# STM32F098xx register map
File version: 1.0
Registers are 32-bit, read-write, reset 0x0 unless marked. A register's access mark holds for its fields unless they carry their own. Offsets are from the block's base; [hi:lo] are bit positions.

## CEC — HDMI-CEC
Base 0x40007800
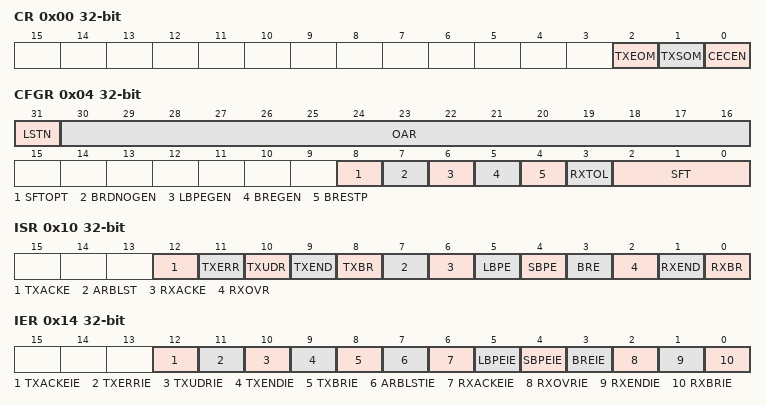
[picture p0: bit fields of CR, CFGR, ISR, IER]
0x00 CR — CEC control register
  [2] TXEOM — CEC Tx End Of Message
  [1] TXSOM — CEC Tx Start Of Message
  [0] CECEN — CEC Enable
0x04 CFGR — CEC configuration register
  [31] LSTN — CEC Listen mode
  [30:16] OAR — CEC Own Address
  [8] SFTOPT — CEC Signal Free Time optional
  [7] BRDNOGEN — CEC Broadcast No Error generation
  [6] LBPEGEN — CEC Long Bit Period Error gener
  [5] BREGEN — CEC Bit Rising Error generation
  [4] BRESTP — CEC Rx Stop
  [3] RXTOL — CEC Tolerance
  [2:0] SFT — CEC Signal Free Time
0x08 TXDR — CEC Tx data register
  [7:0] TXD — CEC Tx Data
0x0C RXDR — CEC Rx Data Register
  [7:0] RXD — CEC Rx Data
0x10 ISR — CEC Interrupt and Status Register
  [12] TXACKE — CEC Tx Missing Acknowledge
  [11] TXERR — CEC Tx-Error
  [10] TXUDR — CEC Tx-Buffer Underrun
  [9] TXEND — CEC End of Transmission
  [8] TXBR — CEC Tx Byte Request
  [7] ARBLST — CEC Arbitration Lost
  [6] RXACKE — CEC Rx Missing Acknowledge
  [5] LBPE — CEC Rx Long Bit period Error
  [4] SBPE — CEC Rx Short Bit period Error
  [3] BRE — CEC Rx Bit Rising Error
  [2] RXOVR — CEC Rx-Overrun
  [1] RXEND — CEC End Of Reception
  [0] RXBR — CEC Rx-Byte Received
0x14 IER — CEC interrupt enable register
  [12] TXACKEIE — CEC Tx Missing Acknowledge IT Enable
  [11] TXERRIE — CEC Tx-Error IT Enable
  [10] TXUDRIE — CEC Tx-Buffer Underrun IT Enable
  [9] TXENDIE — CEC End of Transmission IT Enable
  [8] TXBRIE — CEC Tx Byte Request IT Enable
  [7] ARBLSTIE — CEC Arbitration Lost IT Enable
  [6] RXACKEIE — CEC Rx Missing Acknowledge IT Enable
  [5] LBPEIE — CEC Rx Long Bit period Error IT Enable
  [4] SBPEIE — CEC Rx Short Bit period Error IT Enable
  [3] BREIE — CEC Rx Bit Rising Error IT Enable
  [2] RXOVRIE — CEC Rx-Overrun IT Enable
  [1] RXENDIE — CEC End Of Reception IT Enable
  [0] RXBRIE — CEC Rx-Byte Received IT Enable

## COMP
Base 0x4001001C
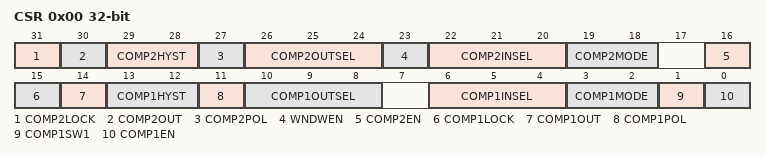
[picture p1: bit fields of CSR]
0x00 CSR — Kept for legacy purpose. Use structure 'COMP_Common_TypeDef'
  [31] COMP2LOCK
  [30] COMP2OUT — COMP2 output level
  [29:28] COMP2HYST — COMP2 hysteresis
  [27] COMP2POL — COMP2 output polarity
  [26:24] COMP2OUTSEL — COMP2 output select
  [23] WNDWEN — COMPx window mode. Bit intended to be used with COMP common instance (COMP_Common_TypeDef)
    0=DISABLE (Window mode disable: Comparators 1 and 2 are independent); 1=COMP1_INPUT_PLUS_COMMON (Window mode enable: Comparators instances pair COMP1 and COMP2 have their input plus connected together. The common input is COMP1 input plus (COMP2 input plus is no more accessible).)
  [22:20] COMP2INSEL — COMP2 inverting input select
  [19:18] COMP2MODE — COMP2 power mode
  [16] COMP2EN — COMP2 enable
  [15] COMP1LOCK
  [14] COMP1OUT — COMP1 output level
  [13:12] COMP1HYST — COMP1 hysteresis
    0=NONE (No hysteresis); 1=LOW (Hysteresis level low); 2=MEDIUM (Hysteresis level medium); 3=HIGH (Hysteresis level high)
  [11] COMP1POL — COMP1 output polarity
    0=NONINVERTED (COMP output polarity is not inverted: comparator output is high when the plus (non-inverting) input is at a higher voltage than the minus (inverting) input); 1=INVERTED (COMP output polarity is inverted: comparator output is low when the plus (non-inverting) input is at a lower voltage than the minus (inverting) input)
  [10:8] COMP1OUTSEL — COMP1 output select
    0=NONE (COMP output is not connected to other peripherals (except GPIO and EXTI that are always connected to COMP output)); 1=TIM1_BKIN (COMP output connected to TIM1 break input (BKIN)); 2=TIM1_IC1 (COMP output connected to TIM1 input capture 1); 3=TIM1_OCCLR (COMP output connected to TIM1 OCREF clear); 4=TIM2_IC4 (COMP output connected to TIM2 input capture 4); 5=TIM2_OCCLR (COMP output connected to TIM2 OCREF clear); 6=TIM3_IC1 (COMP output connected to TIM3 input capture 1); 7=TIM3_OCCLR (COMP output connected to TIM3 OCREF clear)
  [6:4] COMP1INSEL — COMP1 inverting input select
    0=MINUS_1_4VREFINT (Comparator input minus connected to 1/4 VrefInt); 1=MINUS_1_2VREFINT (Comparator input minus connected to 1/2 VrefInt); 2=MINUS_3_4VREFINT (Comparator input minus connected to 3/4 VrefInt); 3=VREFINT (Comparator input minus connected to VrefInt); 4=DAC1_CH1 (Comparator input minus connected to DAC1 channel 1 (DAC_OUT1)); 5=DAC1_CH2 (Comparator input minus connected to DAC1 channel 2 (DAC_OUT2)); 6=IO1 (Comparator input minus connected to IO1 (pin PA0 for COMP1, pin PA2 for COMP2))
  [3:2] COMP1MODE — COMP1 power mode
    0=HIGHSPEED (COMP power mode to high speed); 1=MEDIUMSPEED (COMP power mode to medium speed); 2=LOWPOWER (COMP power mode to low power); 3=ULTRALOWPOWER (COMP power mode to ultra-low power)
  [1] COMP1SW1 — COMP1 SW1 switch control
    0=IO1 (Comparator input plus connected to IO1 (pin PA1 for COMP1, pin PA3 for COMP2)); 1=DAC1_CH1 (Comparator input plus connected to DAC1 channel 1 (DAC_OUT1), through dedicated switch (Note: this switch is solely intended to redirect signals onto high impedance input, such as COMP1 input plus (highly resistive switch)) (specific to COMP instance: COMP1))
  [0] COMP1EN — COMP1 enable
